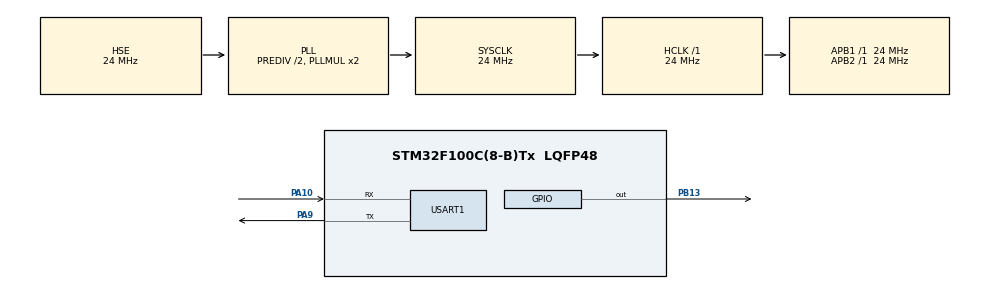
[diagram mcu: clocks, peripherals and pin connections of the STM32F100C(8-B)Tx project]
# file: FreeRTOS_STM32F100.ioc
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FREERTOS.Tasks01=defaultTask,0,128,StartDefaultTask,Default,NULL,Dynamic,NULL,NULL;vLED,-3,128,LEDTimer,Default,NULL,Dynamic,NULL,NULL;vUart,-3,128,Uart,Default,NULL,Dynamic,NULL,NULL
Mcu.Family=STM32F1
Mcu.Name=STM32F100C(8-B)Tx
Mcu.Package=LQFP48
NVIC.PriorityGroup=NVIC_PRIORITYGROUP_4
NVIC.TIM3_IRQn=true\:0\:0\:false\:false\:true\:false\:false\:true
NVIC.TimeBase=TIM3_IRQn
NVIC.TimeBaseIP=TIM3
PA10.Mode=Asynchronous
PA10.Signal=USART1_RX
PA13.Mode=Serial_Wire
PA13.Signal=SYS_JTMS-SWDIO
PA14.Mode=Serial_Wire
PA14.Signal=SYS_JTCK-SWCLK
PA9.Mode=Asynchronous
PA9.Signal=USART1_TX
PB13.Signal=GPIO_Output
PD0-OSC_IN.Mode=HSE-External-Oscillator
PD0-OSC_IN.Signal=RCC_OSC_IN
PD1-OSC_OUT.Mode=HSE-External-Oscillator
PD1-OSC_OUT.Signal=RCC_OSC_OUT
ProjectManager.HeapSize=0x200
ProjectManager.StackSize=0x400
ProjectManager.TargetToolchain=STM32CubeIDE
RCC.AHBFreq_Value=24000000
RCC.APB1Freq_Value=24000000
RCC.APB1TimFreq_Value=24000000
RCC.APB2Freq_Value=24000000
RCC.APB2TimFreq_Value=24000000
RCC.HCLKFreq_Value=24000000
RCC.HSEDivPLL=RCC_HSE_PREDIV_DIV2
RCC.HSE_VALUE=24000000
RCC.PLLSource=RCC_PLLSOURCE_HSE
RCC.SYSCLKFreq_VALUE=24000000
RCC.SYSCLKSource=RCC_SYSCLKSOURCE_PLLCLK
TIM2.Prescaler=23
USART1.VirtualMode=VM_ASYNC
VP_FREERTOS_VS_CMSIS_V1.Mode=CMSIS_V1
VP_SYS_VS_tim3.Mode=TIM3
VP_TIM2_VS_ClockSourceINT.Mode=Internal
board=custom

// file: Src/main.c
/* USER CODE BEGIN Header */
/**
  ******************************************************************************
  * @file           : main.c
  * @brief          : Main program body
  ******************************************************************************
  * @attention
  *
  * <h2><center>&copy; Copyright (c) 2020 STMicroelectronics.
  * All rights reserved.</center></h2>
  *
  * This software component is licensed by ST under BSD 3-Clause license,
  * the "License"; You may not use this file except in compliance with the
  * License. You may obtain a copy of the License at:
  *                        opensource.org/licenses/BSD-3-Clause
  *
  ******************************************************************************
  */
/* USER CODE END Header */

#include "main.h"
#include "cmsis_os.h"

TIM_HandleTypeDef htim2;

UART_HandleTypeDef huart1;

osThreadId defaultTaskHandle;
osThreadId vLEDHandle;
osThreadId vUartHandle;

void SystemClock_Config(void);
static void MX_GPIO_Init(void);
static void MX_TIM2_Init(void);
static void MX_USART1_UART_Init(void);
void StartDefaultTask(void const * argument);
void LEDTimer(void const * argument);
void Uart(void const * argument);

int main(void)
{

  /* MCU Configuration--------------------------------------------------------*/

  /* Reset of all peripherals, Initializes the Flash interface and the Systick. */
  HAL_Init();

  /* Configure the system clock */
  SystemClock_Config();

  /* Initialize all configured peripherals */
  MX_GPIO_Init();
  MX_TIM2_Init();
  MX_USART1_UART_Init();

  /* Create the thread(s) */
  /* definition and creation of defaultTask */
  osThreadDef(defaultTask, StartDefaultTask, osPriorityNormal, 0, 128);
  defaultTaskHandle = osThreadCreate(osThread(defaultTask), NULL);

  /* definition and creation of vLED */
  osThreadDef(vLED, LEDTimer, osPriorityIdle, 0, 128);
  vLEDHandle = osThreadCreate(osThread(vLED), NULL);

  /* definition and creation of vUart */
  osThreadDef(vUart, Uart, osPriorityIdle, 0, 128);
  vUartHandle = osThreadCreate(osThread(vUart), NULL);

  /* Start scheduler */
  osKernelStart();

  /* We should never get here as control is now taken by the scheduler */

  /* Infinite loop */
  while (1)
  {

  }
}

void SystemClock_Config(void)
{
  RCC_OscInitTypeDef RCC_OscInitStruct = {0};
  RCC_ClkInitTypeDef RCC_ClkInitStruct = {0};

  /** Initializes the CPU, AHB and APB busses clocks
  */
  RCC_OscInitStruct.OscillatorType = RCC_OSCILLATORTYPE_HSE;
  RCC_OscInitStruct.HSEState = RCC_HSE_ON;
  RCC_OscInitStruct.HSEPredivValue = RCC_HSE_PREDIV_DIV2;
  RCC_OscInitStruct.PLL.PLLState = RCC_PLL_ON;
  RCC_OscInitStruct.PLL.PLLSource = RCC_PLLSOURCE_HSE;
  RCC_OscInitStruct.PLL.PLLMUL = RCC_PLL_MUL2;
  if (HAL_RCC_OscConfig(&RCC_OscInitStruct) != HAL_OK)
  {
    Error_Handler();
  }
  /** Initializes the CPU, AHB and APB busses clocks
  */
  RCC_ClkInitStruct.ClockType = RCC_CLOCKTYPE_HCLK|RCC_CLOCKTYPE_SYSCLK
                              |RCC_CLOCKTYPE_PCLK1|RCC_CLOCKTYPE_PCLK2;
  RCC_ClkInitStruct.SYSCLKSource = RCC_SYSCLKSOURCE_PLLCLK;
  RCC_ClkInitStruct.AHBCLKDivider = RCC_SYSCLK_DIV1;
  RCC_ClkInitStruct.APB1CLKDivider = RCC_HCLK_DIV1;
  RCC_ClkInitStruct.APB2CLKDivider = RCC_HCLK_DIV1;

  if (HAL_RCC_ClockConfig(&RCC_ClkInitStruct, FLASH_LATENCY_0) != HAL_OK)
  {
    Error_Handler();
  }
}

static void MX_TIM2_Init(void)
{

  TIM_ClockConfigTypeDef sClockSourceConfig = {0};
  TIM_MasterConfigTypeDef sMasterConfig = {0};

  htim2.Instance = TIM2;
  htim2.Init.Prescaler = 23;
  htim2.Init.CounterMode = TIM_COUNTERMODE_UP;
  htim2.Init.Period = 0;
  htim2.Init.ClockDivision = TIM_CLOCKDIVISION_DIV1;
  htim2.Init.AutoReloadPreload = TIM_AUTORELOAD_PRELOAD_DISABLE;
  if (HAL_TIM_Base_Init(&htim2) != HAL_OK)
  {
    Error_Handler();
  }
  sClockSourceConfig.ClockSource = TIM_CLOCKSOURCE_INTERNAL;
  if (HAL_TIM_ConfigClockSource(&htim2, &sClockSourceConfig) != HAL_OK)
  {
    Error_Handler();
  }
  sMasterConfig.MasterOutputTrigger = TIM_TRGO_RESET;
  sMasterConfig.MasterSlaveMode = TIM_MASTERSLAVEMODE_DISABLE;
  if (HAL_TIMEx_MasterConfigSynchronization(&htim2, &sMasterConfig) != HAL_OK)
  {
    Error_Handler();
  }

}

static void MX_USART1_UART_Init(void)
{

  huart1.Instance = USART1;
  huart1.Init.BaudRate = 115200;
  huart1.Init.WordLength = UART_WORDLENGTH_8B;
  huart1.Init.StopBits = UART_STOPBITS_1;
  huart1.Init.Parity = UART_PARITY_NONE;
  huart1.Init.Mode = UART_MODE_TX_RX;
  huart1.Init.HwFlowCtl = UART_HWCONTROL_NONE;
  huart1.Init.OverSampling = UART_OVERSAMPLING_16;
  if (HAL_UART_Init(&huart1) != HAL_OK)
  {
    Error_Handler();
  }

}

static void MX_GPIO_Init(void)
{
  GPIO_InitTypeDef GPIO_InitStruct = {0};

  /* GPIO Ports Clock Enable */
  __HAL_RCC_GPIOD_CLK_ENABLE();
  __HAL_RCC_GPIOB_CLK_ENABLE();
  __HAL_RCC_GPIOA_CLK_ENABLE();

  /*Configure GPIO pin Output Level */
  HAL_GPIO_WritePin(GPIOB, GPIO_PIN_14, GPIO_PIN_RESET);

  /*Configure GPIO pin : PB13 */
  GPIO_InitStruct.Pin = GPIO_PIN_14;
  GPIO_InitStruct.Mode = GPIO_MODE_OUTPUT_PP;
  GPIO_InitStruct.Pull = GPIO_NOPULL;
  GPIO_InitStruct.Speed = GPIO_SPEED_FREQ_LOW;
  HAL_GPIO_Init(GPIOB, &GPIO_InitStruct);

}

void StartDefaultTask(void const * argument)
{
  for(;;)
  {
    osDelay(1);
  }
}

void LEDTimer(void const * argument)
{
  /* USER CODE BEGIN LEDTimer */
  /* Infinite loop */
  for(;;)
  {
    //osDelay(1000);
    HAL_GPIO_WritePin(GPIOB,GPIO_PIN_14,GPIO_PIN_RESET);
	HAL_Delay(1000);
    HAL_GPIO_WritePin(GPIOB,GPIO_PIN_14,GPIO_PIN_SET);
	HAL_Delay(1000);

  }
  /* USER CODE END LEDTimer */
}

void Uart(void const * argument)
{
  /* USER CODE BEGIN Uart */
	uint8_t pData[]="hello world";//通过字符串数组定义“hello world”字符串
  /* Infinite loop */
  for(;;)
  {
    osDelay(1000);
	HAL_UART_Transmit(&huart1,(uint8_t*)pData,sizeof(pData),100);//不断通过串口1发送，pData中的数据，sizeof计算pData中的字节数
  }
  /* USER CODE END Uart */
}

void HAL_TIM_PeriodElapsedCallback(TIM_HandleTypeDef *htim)
{
  if (htim->Instance == TIM3) {
    HAL_IncTick();
  }
}

void Error_Handler(void)
{
}

/************************ (C) COPYRIGHT STMicroelectronics *****END OF FILE****/
